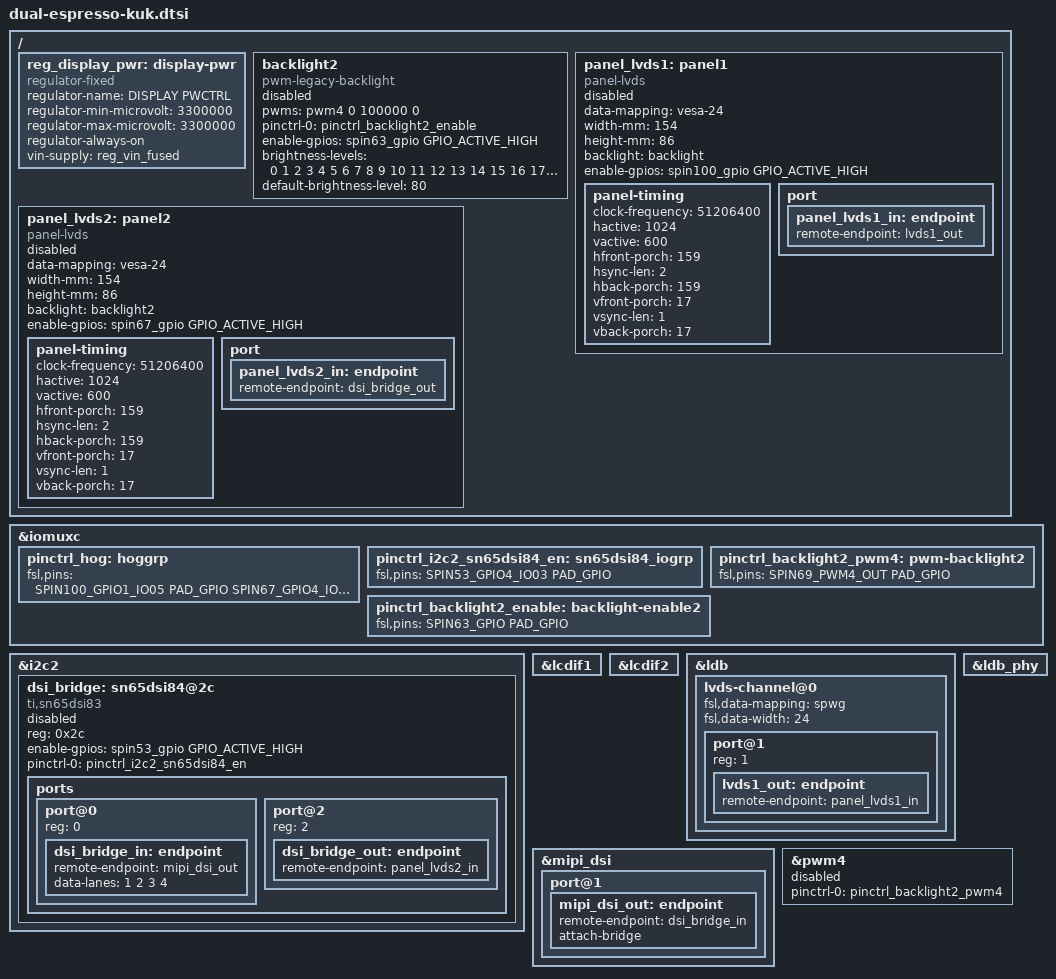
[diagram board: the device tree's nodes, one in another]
/*
 * Copyright 2021 Garz & Fricke GmbH
 *
 */

/*
Remarks:
    - Use ETHERNET_ONLY_100MBIT for dual espresso board
Defines:
*/

/ {
#if 0
	reg_vin_fused: vin_fused {
		compatible = "regulator-fixed";
		regulator-name = "VIN_FUSED";
		regulator-min-microvolt = <12000000>;
		/* max	should be 24V but the fixed regulator driver does
		not allow a range here */
		regulator-max-microvolt = <12000000>;
		regulator-always-on;
	};

	reg_board_5v: 5v {
		compatible = "regulator-fixed";
		regulator-name = "+5V";
		regulator-min-microvolt = <5000000>;
		regulator-max-microvolt = <5000000>;
		regulator-always-on;
		vin-supply = <&reg_vin_fused>;
	};

	reg_3v3: 3v3 {
		compatible = "regulator-fixed";
		regulator-name = "+3V3";
		regulator-min-microvolt = <3300000>;
		regulator-max-microvolt = <3300000>;
		regulator-always-on;
		vin-supply = <&reg_vin_fused>;
	};
#endif
	reg_display_pwr: display-pwr {
		compatible = "regulator-fixed";
		regulator-name = "DISPLAY PWCTRL";
		regulator-min-microvolt = <3300000>;
		regulator-max-microvolt = <3300000>;
		regulator-always-on;
		vin-supply = <&reg_vin_fused>;
	};

};

/ {
	backlight2: backlight2 {
		compatible = "pwm-legacy-backlight";
		pwms = <&pwm4 0 100000 0>;
		pinctrl-0 = <&pinctrl_backlight2_enable>;
		enable-gpios = <spin63_gpio GPIO_ACTIVE_HIGH>;
		brightness-levels = < 0  1  2  3  4  5  6  7  8  9
				     10 11 12 13 14 15 16 17 18 19
				     20 21 22 23 24 25 26 27 28 29
				     30 31 32 33 34 35 36 37 38 39
				     40 41 42 43 44 45 46 47 48 49
				     50 51 52 53 54 55 56 57 58 59
				     60 61 62 63 64 65 66 67 68 69
				     70 71 72 73 74 75 76 77 78 79
				     80 81 82 83 84 85 86 87 88 89
				     90 91 92 93 94 95 96 97 98 99
				    100>;
		default-brightness-level = <80>;
		//status = "okay";
		status = "disabled";
	};

	panel_lvds1: panel1 {
		status          = "disabled";
		compatible      = "panel-lvds";
		data-mapping = "vesa-24";
		width-mm = <154>;
		height-mm = <86>;
		backlight = <&backlight>;
		enable-gpios = <spin100_gpio GPIO_ACTIVE_HIGH>;

		panel-timing {
			clock-frequency = <51206400>;
			hactive = <1024>;
			vactive = <600>;
			hfront-porch = <159>;
			hsync-len = <2>;
			hback-porch = <159>;
			vfront-porch = <17>;
			vsync-len = <1>;
			vback-porch = <17>;
		};

		port {
			panel_lvds1_in: endpoint {
				remote-endpoint = <&lvds1_out>;
			};
		};
	};

	panel_lvds2: panel2 {
		status          = "disabled";
		compatible      = "panel-lvds";
		data-mapping = "vesa-24";
		width-mm = <154>;
		height-mm = <86>;
		backlight = <&backlight2>;
		enable-gpios = <spin67_gpio GPIO_ACTIVE_HIGH>;

		panel-timing {
			clock-frequency = <51206400>;
			hactive = <1024>;
			vactive = <600>;
			hfront-porch = <159>;
			hsync-len = <2>;
			hback-porch = <159>;
			vfront-porch = <17>;
			vsync-len = <1>;
			vback-porch = <17>;
		};

		port {
			panel_lvds2_in: endpoint {
				remote-endpoint = <&dsi_bridge_out>;
			};
		};
	};
};

&iomuxc {

	pinctrl_hog: hoggrp {
		fsl,pins = <
			SPIN100_GPIO1_IO05	PAD_GPIO	/* LCD1_VCC_ON */
			SPIN67_GPIO4_IO08	PAD_GPIO	/* LCD2_VCC_ON */
		>;
	};

	pinctrl_i2c2_sn65dsi84_en: sn65dsi84_iogrp {
		fsl,pins = < SPIN53_GPIO4_IO03  PAD_GPIO >;		/* SODIMM  Pin 53 MIPI_DSI_EN*/
	};

	pinctrl_backlight2_pwm4: pwm-backlight2 {
		fsl,pins = < SPIN69_PWM4_OUT		PAD_GPIO >;	/* BACKLIGHT2_PWM */
	};

	pinctrl_backlight2_enable: backlight-enable2 {
		fsl,pins = < SPIN63_GPIO		PAD_GPIO >;	/* BACKLIGHT_ENABLE SODIMM Pin 63 */
	};

};


&i2c2 {

	dsi_bridge: sn65dsi84@2c {
		//status = "okay";
		status = "disabled";
		compatible = "ti,sn65dsi83";
		reg = <0x2c>;
		enable-gpios =<spin53_gpio GPIO_ACTIVE_HIGH>;
		pinctrl-names = "default";
		pinctrl-0 = <&pinctrl_i2c2_sn65dsi84_en>;

		ports {
			#address-cells = <1>;
			#size-cells = <0>;
			port@0 {
				reg = <0>;
				dsi_bridge_in: endpoint {
					remote-endpoint = <&mipi_dsi_out>;
					data-lanes = <1 2 3 4>;
				};
			};
			port@2 {
				reg = <2>;
				dsi_bridge_out: endpoint {
					remote-endpoint = <&panel_lvds2_in>;
				};
			};
		};
	};
};


&lcdif1 {
	status = "okay";
};

&lcdif2 {
	status = "okay";
};

&ldb {
	status = "okay";
	lvds-channel@0 {
		status = "okay";
		fsl,data-mapping = "spwg";
		fsl,data-width = <24>;
		port@1 {
			reg = <1>;
			lvds1_out: endpoint {
				remote-endpoint = <&panel_lvds1_in>;
			};
		};
	};
};

&ldb_phy {
	status = "okay";
};

&mipi_dsi {
	status = "okay";

	port@1 {
		mipi_dsi_out: endpoint {
			remote-endpoint = <&dsi_bridge_in>;
			attach-bridge;
		};
	};
};
/*
&pwm1 {
	pinctrl-names = "default";
	pinctrl-0 = <&pinctrl_backlight_pwm1>;
	status = "okay";
};
*/

&pwm4 {
	pinctrl-names = "default";
	pinctrl-0 = <&pinctrl_backlight2_pwm4>;
	//status = "okay";
	status = "disabled";
};

